AUTOSAR XML (schema 00045)
package /Esm
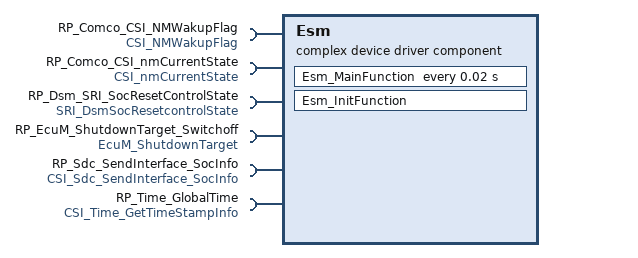
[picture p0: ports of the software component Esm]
  complex device driver sw component type Esm  # Ecu State Management
    6 x require port:
      RP_Comco_CSI_NMWakupFlag: required-interface=CSI_NMWakupFlag
      RP_Comco_CSI_nmCurrentState: required-interface=CSI_nmCurrentState
      RP_Dsm_SRI_SocResetControlState: required-interface=SRI_DsmSocResetcontrolState
      RP_EcuM_ShutdownTarget_Switchoff: required-interface=EcuM_ShutdownTarget
      RP_Sdc_SendInterface_SocInfo: required-interface=CSI_Sdc_SendInterface_SocInfo
      RP_Time_GlobalTime: required-interface=CSI_Time_GetTimeStampInfo
    behavior Esm_IB: handle-termination-and-restart=NO-SUPPORT
      init event InitEvent_Esm_InitFunction: start-on-event=Esm_InitFunction
      timing event TimingEvent_Esm_MainFunction: start-on-event=Esm_MainFunction, period=0.02
      runnable Esm_InitFunction
      runnable Esm_MainFunction
        data-receive-point-by-arguments:
          access drparg_DE_SocRersetControlSt: accessed-variable=RP_Dsm_SRI_SocResetControlState.DE_SocRersetControlState
        5 x sync call, all with timeout=0.0:
          scp_GetTimeStampMs: operation=RP_Time_GlobalTime.GetTimeStampMs
          scp_NMWakupFlag: operation=RP_Comco_CSI_NMWakupFlag.NMWakupFlag
          scp_SelectShutdownTarget: operation=RP_EcuM_ShutdownTarget_Switchoff.SelectShutdownTarget
          scp_SocShutdownReuqest: operation=RP_Sdc_SendInterface_SocInfo.SocShutdownReuqest
          scp_nmCurrentState: operation=RP_Comco_CSI_nmCurrentState.nmCurrentState
  swc implementation EsmImpl: programming-language=C, sw-version=1.0.0, vendor-id=0, behavior=Esm_IB
    code-descriptors:
      code CodeGen: artifact-descriptors=[{short-label=SWHDR, category=SWHDR}, {short-label=SWSRC, category=SWSRC}]
    resource consumption Resource
      4 x memory section:
        CALIB: sw-addrmethod=CALIB
        CODE: sw-addrmethod=CODE
        CODE_LOCAL: options=coreLocal, sw-addrmethod=CODE_LOCAL
        VAR_INIT_LOCAL: options=coreLocal, sw-addrmethod=VAR_CLEARED_LOCAL
